# MCXC444 register map
Vendor: NXP Semiconductors; Series: MCX; File version: 1.6
CPU: CM0PLUS r0p0, little endian, no MPU, no FPU, VTOR, 2 interrupt priority bits
Registers are 32-bit, read-write, reset 0x0 unless marked. A register's access mark holds for its fields unless they carry their own. Offsets are from the block's base; [hi:lo] are bit positions; 'fields as' and 'values as' point back to an identical list.

## CMP0 — High-Speed Comparator (CMP), Voltage Reference (VREF) Digital-to-Analog Converter (DAC), and Analog Mux (ANMUX)
Base 0x40073000; register names take the prefix CMP0_
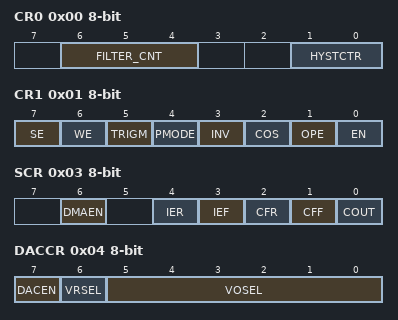
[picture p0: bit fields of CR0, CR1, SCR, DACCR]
0x00 CR0 8-bit — CMP Control Register 0
  [6:4] FILTER_CNT — Filter Sample Count
    0=b000 (Filter is disabled. SE = 0, COUT = COUTA.); 1=b001 (One sample must agree. The comparator output is simply sampled.); 2=b010 (2 consecutive samples must agree.); 3=b011 (3 consecutive samples must agree.); 4=b100 (4 consecutive samples must agree.); 5=b101 (5 consecutive samples must agree.); 6=b110 (6 consecutive samples must agree.); 7=b111 (7 consecutive samples must agree.)
  [1:0] HYSTCTR — Comparator hard block hysteresis control
    0=b00 (Level 0); 1=b01 (Level 1); 2=b10 (Level 2); 3=b11 (Level 3)
0x01 CR1 8-bit — CMP Control Register 1
  [7] SE — Sample Enable
    0=b0 (Sampling mode is not selected.); 1=b1 (Sampling mode is selected.)
  [6] WE — Windowing Enable
    0=b0 (Windowing mode is not selected.); 1=b1 (Windowing mode is selected.)
  [5] TRIGM — Trigger Mode Enable
    0=b0 (Trigger mode is disabled.); 1=b1 (Trigger mode is enabled.)
  [4] PMODE — Power Mode Select
    0=b0 (Low-Speed (LS) Comparison mode selected. In this mode, CMP has slower output propagation delay and lower current consumption.); 1=b1 (High-Speed (HS) Comparison mode selected. In this mode, CMP has faster output propagation delay and higher current consumption.)
  [3] INV — Comparator INVERT
    0=b0 (Does not invert the comparator output.); 1=b1 (Inverts the comparator output.)
  [2] COS — Comparator Output Select
    0=b0 (Set the filtered comparator output (CMPO) to equal COUT.); 1=b1 (Set the unfiltered comparator output (CMPO) to equal COUTA.)
  [1] OPE — Comparator Output Pin Enable
    0=b0 (CMPO is not available on the associated CMPO output pin. If the comparator does not own the pin, this field has no effect.); 1=b1 (CMPO is available on the associated CMPO output pin. The comparator output (CMPO) is driven out on the associated CMPO output pin if the comparator owns the pin. If the comparator does not own the field, this bit has no effect.)
  [0] EN — Comparator Module Enable
    0=b0 (Analog Comparator is disabled.); 1=b1 (Analog Comparator is enabled.)
0x02 FPR 8-bit — CMP Filter Period Register
  [7:0] FILT_PER — Filter Sample Period
0x03 SCR 8-bit — CMP Status and Control Register
  [6] DMAEN — DMA Enable Control
    0=b0 (DMA is disabled.); 1=b1 (DMA is enabled.)
  [4] IER — Comparator Interrupt Enable Rising
    0=b0 (Interrupt is disabled.); 1=b1 (Interrupt is enabled.)
  [3] IEF — Comparator Interrupt Enable Falling
    0=b0 (Interrupt is disabled.); 1=b1 (Interrupt is enabled.)
  [2] CFR — Analog Comparator Flag Rising
    0=b0 (Rising-edge on COUT has not been detected.); 1=b1 (Rising-edge on COUT has occurred.)
  [1] CFF — Analog Comparator Flag Falling
    0=b0 (Falling-edge on COUT has not been detected.); 1=b1 (Falling-edge on COUT has occurred.)
  [0] COUT ro — Analog Comparator Output
0x04 DACCR 8-bit — DAC Control Register
  [7] DACEN — DAC Enable
    0=b0 (DAC is disabled.); 1=b1 (DAC is enabled.)
  [6] VRSEL — Supply Voltage Reference Source Select
    0=b0 (Vin1 is selected as resistor ladder network supply reference.); 1=b1 (Vin2 is selected as resistor ladder network supply reference.)
  [5:0] VOSEL — DAC Output Voltage Select
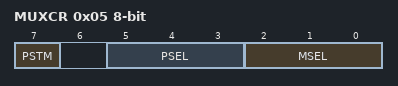
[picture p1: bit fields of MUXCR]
0x05 MUXCR 8-bit — MUX Control Register
  [7] PSTM — Pass Through Mode Enable
    0=b0 (Pass Through Mode is disabled.); 1=b1 (Pass Through Mode is enabled.)
  [5:3] PSEL — Plus Input Mux Control
    0=b000 (IN0); 1=b001 (IN1); 2=b010 (IN2); 3=b011 (IN3); 4=b100 (IN4); 5=b101 (IN5); 6=b110 (IN6); 7=b111 (IN7)
  [2:0] MSEL — Minus Input Mux Control
    values as PSEL
